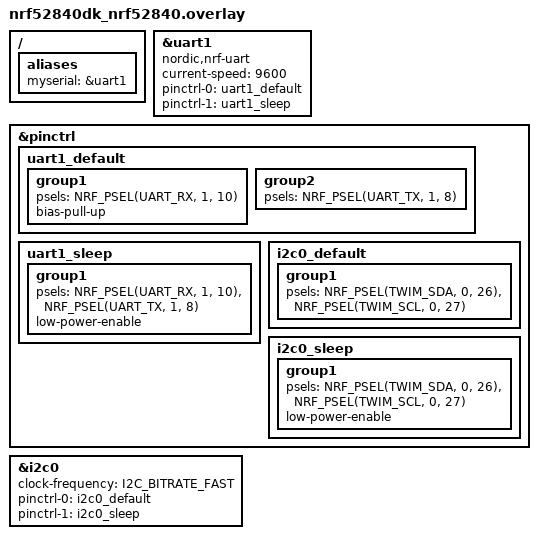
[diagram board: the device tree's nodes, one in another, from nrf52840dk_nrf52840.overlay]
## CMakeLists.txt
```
cmake_minimum_required(VERSION 3.20.0)
find_package(Zephyr REQUIRED HINTS $ENV{ZEPHYR_BASE})
project(CO2_LCD_example)

target_sources(app PRIVATE
    src/main.c
    src/LCD.c
    src/uart_co2.c
)

target_include_directories(app PRIVATE include)
```

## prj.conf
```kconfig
# UART (MH-Z14A) 설정
CONFIG_UART_INTERRUPT_DRIVEN=y
CONFIG_UART_ASYNC_API=y
CONFIG_LOG=y

# I2C (LCD) 설정
CONFIG_GPIO=y
CONFIG_I2C=y
CONFIG_MAIN_STACK_SIZE=2048
CONFIG_HEAP_MEM_POOL_SIZE=2048

# 로깅 (디버깅용)
CONFIG_LOG=y
```

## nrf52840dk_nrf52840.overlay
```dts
// To get started, press Ctrl+Space to bring up the completion menu and view the available nodes.

// You can also use the buttons in the sidebar to perform actions on nodes.
// Actions currently available include:

// * Enabling / disabling the node
// * Adding the bus to a bus
// * Removing the node
// * Connecting ADC channels

// For more help, browse the DeviceTree documentation at https://docs.zephyrproject.org/latest/guides/dts/index.html
// You can also visit the nRF DeviceTree extension documentation at https://nrfconnect.github.io/vscode-nrf-connect/devicetree/nrfdevicetree.html

/ {
    aliases {
        myserial = &uart1;
    };
};

// &uart0 {
//     status = "disabled";
// };

arduino_serial: &uart1 {
    status = "okay";
    compatible = "nordic,nrf-uart";
	current-speed = <9600>;
	pinctrl-0 = <&uart1_default>;
	pinctrl-1 = <&uart1_sleep>;
	pinctrl-names = "default", "sleep";
};

&pinctrl {
	uart1_default: uart1_default {
		group1 {
			psels = <NRF_PSEL(UART_RX, 1, 10)>;
			bias-pull-up;
		};
		group2 {
			psels = <NRF_PSEL(UART_TX, 1, 8)>;
		};
	};

	uart1_sleep: uart1_sleep {
		group1 {
			psels = <NRF_PSEL(UART_RX, 1, 10)>,
				<NRF_PSEL(UART_TX, 1, 8)>;
			low-power-enable;
		};
	};

    i2c0_default: i2c0_default {
        group1 {
            psels = <NRF_PSEL(TWIM_SDA, 0, 26)>, <NRF_PSEL(TWIM_SCL, 0, 27)>;
        };
    };

    i2c0_sleep: i2c0_sleep {
        group1 {
            psels = <NRF_PSEL(TWIM_SDA, 0, 26)>, <NRF_PSEL(TWIM_SCL, 0, 27)>;
            low-power-enable;
        };
    };
};


&i2c0 {
    status = "okay";
    clock-frequency = <I2C_BITRATE_FAST>;

    pinctrl-0 = <&i2c0_default>;
    pinctrl-1 = <&i2c0_sleep>;
    pinctrl-names = "default", "sleep";
};
```

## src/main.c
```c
#include <zephyr/kernel.h>
#include <zephyr/device.h>
#include <zephyr/drivers/uart.h>
#include <zephyr/sys/printk.h>
#include <string.h>
#include <stdio.h>
#include "uart_co2.h"
#include "LCD.h"

int main(void)
{
    /* LCD 초기화 */
    LCD_TWI_init();
    LCD_begin(16, 2, LCD_5x8DOTS);
    LCD_clear();
    LCD_backlight();

    /* UART CO2 센서 초기화 */
    const struct device *uart_dev = DEVICE_DT_GET(DT_ALIAS(myserial));
    if (!device_is_ready(uart_dev)) {
        printk("UART device not ready\n");
        return;
    }
    uart_irq_callback_user_data_set(uart_dev, uart_co2_serial_callback, NULL);
    uart_irq_rx_enable(uart_dev);

    char packet[MSG_SIZE];
    while (1) {
        /* CO2 측정 요청 전송 */
        uart_co2_send_request();

        /* 메시지 큐에서 응답 대기 */
        if (k_msgq_get(&uart_co2_msgq, packet, K_MSEC(2000)) == 0) {
            int ppm = uart_co2_get_ppm(packet);
            char display[32];

            /* 체크섬 오류 또는 데이터 이상 시 에러 표시 */
            if (ppm < 0) {
                snprintf(display, sizeof(display), "CO2 Error");
            } else {
                snprintf(display, sizeof(display), "CO2: %4d ppm", ppm);
            }

            /* LCD에 출력 */
            LCD_clear();
            LCD_setCursor(0, 0);
            LCD_print((uint8_t *)display, strlen(display) + 1);
        } else {
            /* 타임아웃 시 표시 */
            const char *timeout_msg = "No Data";
            LCD_clear();
            LCD_setCursor(0, 0);
            LCD_print((uint8_t *)timeout_msg, strlen(timeout_msg) + 1);
        }

        /* 2초 대기 후 반복 */
        k_msleep(2000);
    }

    return 0;
}
```

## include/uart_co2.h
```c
// MH-Z14A sensor

#ifndef UART_CO2_H
#define UART_CO2_H

#include <zephyr/kernel.h>
#include <zephyr/device.h>
#include <zephyr/drivers/uart.h>

#ifdef __cplusplus
extern "C" {
#endif

/* 수신 타임아웃(ms) */
#define RECEIVE_TIMEOUT 1000
/* 패킷 크기 */
#define MSG_SIZE 9
/* CO₂ 농도 계산용 상수 */
#define CO2_MULTIPLIER 256

/* 메시지 큐 선언 (소스 파일에서 정의) */
extern struct k_msgq uart_co2_msgq;

/**
 * @brief UART 인터럽트 콜백 함수
 * @param dev      UART 디바이스 포인터
 * @param user_data  사용자 데이터 (unused)
 */
void uart_co2_serial_callback(const struct device *dev, void *user_data);

/**
 * @brief CO₂ 측정 명령 전송
 */
void uart_co2_send_request(void);

/**
 * @brief 패킷에서 CO₂ 농도(ppm) 계산
 * @param packet  수신된 9바이트 패킷
 * @return 체크섬 오류 시 -1, 정상 시 ppm 값
 */
int uart_co2_get_ppm(const char *packet);

#ifdef __cplusplus
}
#endif

#endif /* UART_CO2_H */
```

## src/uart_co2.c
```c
// MH-Z14A sensor

#include "uart_co2.h"
#include <string.h>

/* 메시지 큐 정의: 최대 9바이트 메시지 9개 저장, align=4 */
K_MSGQ_DEFINE(uart_co2_msgq, MSG_SIZE, 9, 4);

/* UART 디바이스 바인딩 (DT_ALIAS 로 설정) */
static const struct device *const uart_dev = DEVICE_DT_GET(DT_N_ALIAS_myserial);

/* 수신 버퍼 및 상태 머신 변수 */
static char rx_buf[MSG_SIZE];
static int rx_pos;
static enum {
    UART_FSM_IDLE,
    UART_FSM_HEADER,
    UART_FSM_DATA,
    UART_FSM_CHECKSUM,
    UART_FSM_END,
} uart_fsm = UART_FSM_IDLE;

/* 상태 머신 업데이트 */
static void uart_co2_fsm_update(uint8_t byte)
{
    switch (uart_fsm) {
    case UART_FSM_IDLE:
        if (byte == 0xFF) uart_fsm = UART_FSM_HEADER;
        break;
    case UART_FSM_HEADER:
        if (byte == 0x86) uart_fsm = UART_FSM_DATA;
        else uart_fsm = UART_FSM_IDLE;
        break;
    case UART_FSM_DATA:
        if (rx_pos == MSG_SIZE - 2) uart_fsm = UART_FSM_CHECKSUM;
        break;
    case UART_FSM_CHECKSUM:
        if (rx_pos == MSG_SIZE - 1) uart_fsm = UART_FSM_END;
        break;
    case UART_FSM_END:
        uart_fsm = UART_FSM_IDLE;
        break;
    default:
        uart_fsm = UART_FSM_IDLE;
        break;
    }
}

/* 체크섬 계산 */
static uint8_t uart_co2_calc_checksum(const char *pkt)
{
    uint8_t sum = 0;
    for (int i = 1; i < 8; i++) {
        sum += pkt[i];
    }
    return (uint8_t)(0xFF - sum + 1);
}

/* BCD 형식 → 10진 변환 */
static uint8_t uart_co2_bcd_to_dec(uint8_t bcd)
{
    return (bcd / 16) * 10 + (bcd % 16);
}

void uart_co2_serial_callback(const struct device *dev, void *user_data)
{
    uint8_t byte;
    int read;

    if (!uart_irq_update(uart_dev) || !uart_irq_rx_ready(uart_dev)) {
        return;
    }

    /* FIFO에서 바이트 단위로 읽어들임 */
    while ((read = uart_fifo_read(uart_dev, &byte, 1)) == 1) {
        if (uart_fsm == UART_FSM_IDLE) {
            rx_pos = 0;
        }
        uart_co2_fsm_update(byte);

        if (rx_pos < MSG_SIZE) {
            rx_buf[rx_pos++] = byte;
        }
    }

    /* 패킷 완성되면 메시지 큐에 복사 */
    if (uart_fsm == UART_FSM_END && rx_pos == MSG_SIZE) {
        uint8_t cs = uart_co2_calc_checksum(rx_buf);
        if (cs == (uint8_t)rx_buf[8]) {
            /* 큐에 성공 패킷 전달 (타임아웃 적용 가능) */
            k_msgq_put(&uart_co2_msgq, rx_buf, K_MSEC(RECEIVE_TIMEOUT));
        }
        /* 버퍼 초기화 */
        memset(rx_buf, 0, MSG_SIZE);
        uart_fsm = UART_FSM_IDLE;
    }
}

void uart_co2_send_request(void)
{
    const uint8_t cmd[MSG_SIZE] = {0xFF,0x01,0x86,0,0,0,0,0,0x79};
    for (int i = 0; i < MSG_SIZE; i++) {
        uart_poll_out(uart_dev, cmd[i]);
    }
}

int uart_co2_get_ppm(const char *packet)
{
    if (uart_co2_calc_checksum(packet) != (uint8_t)packet[8]) {
        return -1;
    }
    uint8_t high = uart_co2_bcd_to_dec((uint8_t)packet[2]);
    uint8_t low  = uart_co2_bcd_to_dec((uint8_t)packet[3]);
    return high * CO2_MULTIPLIER + low;
}
```
